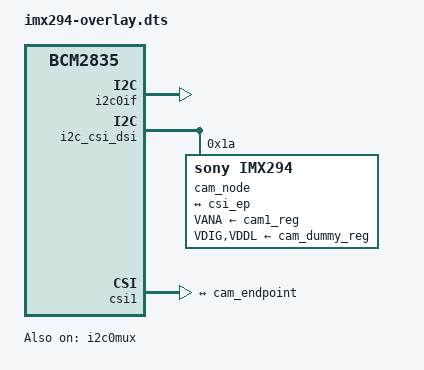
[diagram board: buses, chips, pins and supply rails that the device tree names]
// SPDX-License-Identifier: GPL-2.0-only
// Definitions for IMX294 camera module on VC I2C bus
/dts-v1/;
/plugin/;
/{
	compatible = "brcm,bcm2835";

	fragment@0 {
		target = <&i2c0if>;
		__overlay__ {
			status = "okay";
		};
	};

	clk_frag: fragment@1 {
		target = <&cam1_clk>;
		cam_clk: __overlay__ {
			clock-frequency = <24000000>;
			status = "okay";
		};
	};

	fragment@2 {
		target = <&i2c0mux>;
		__overlay__ {
			status = "okay";
		};
	};

	reg_frag: fragment@3 {
		target = <&cam1_reg>;
		cam_reg: __overlay__ {
			startup-delay-us = <300000>;
		};
	};

	i2c_frag: fragment@100 {
		target = <&i2c_csi_dsi>;
		__overlay__ {
			#address-cells = <1>;
			#size-cells = <0>;
			status = "okay";

			cam_node: imx294@1a {
				reg = <0x1a>;
				status = "okay";
				compatible = "sony,imx294";
				clocks = <&cam1_clk>;
				clock-names = "xclk";

				VANA-supply = <&cam1_reg>;	/* 2.8v */
				VDIG-supply = <&cam_dummy_reg>;	/* 1.2v */
				VDDL-supply = <&cam_dummy_reg>;	/* 1.8v */

				rotation = <0>;
				orientation = <0>;

				port {
					cam_endpoint: endpoint {
						clock-lanes = <0>;
						data-lanes = <1 2 3 4>;
						clock-noncontinuous;
						remote-endpoint = <&csi_ep>;
						link-frequencies =
							/bits/ 64 <450000000>;
					};
				};

			};

		};
	};

	csi_frag: fragment@101 {
		target = <&csi1>;
		csi: __overlay__ {
			status = "okay";
			brcm,media-controller;

			port {
				csi_ep: endpoint {
					remote-endpoint = <&cam_endpoint>;
					clock-lanes = <0>;
					data-lanes = <1 2 3 4>;
					clock-noncontinuous;
				};
			};
		};
	};

	__overrides__ {
		rotation = <&cam_node>,"rotation:0";
		orientation = <&cam_node>,"orientation:0";
		media-controller = <&csi>,"brcm,media-controller?";
	};
};
